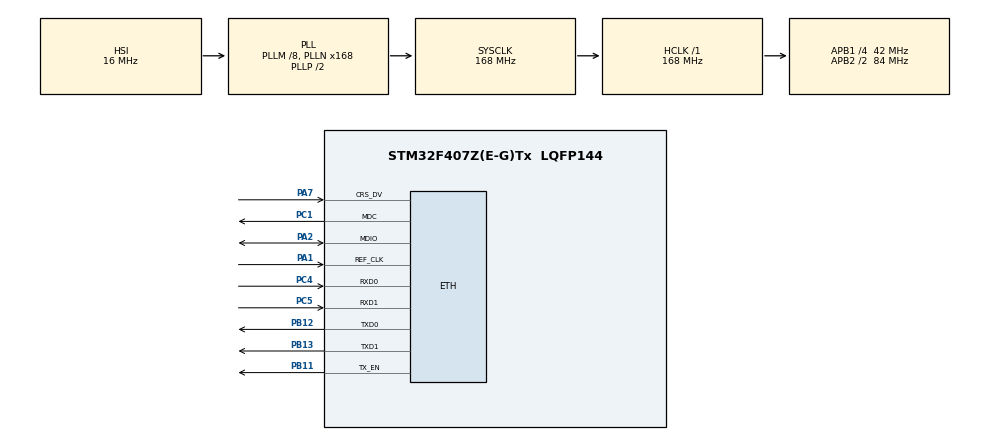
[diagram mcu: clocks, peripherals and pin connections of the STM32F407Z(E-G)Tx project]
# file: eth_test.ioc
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ETH.MediaInterface=HAL_ETH_RMII_MODE
LWIP.BSP.number=1
LWIP.MEM_SIZE=3000
LWIP.Version=v2.1.2_Cube
LWIP0.BSP.STBoard=false
LWIP0.BSP.api=BSP_COMPONENT_DRIVER
LWIP0.BSP.component=LAN8742
LWIP0.BSP.i2caddr=0
LWIP0.BSP.instance=LAN8742
LWIP0.BSP.name=Driver_PHY
LWIP0.BSP.semaphore=S_LAN8742
LWIP0.BSP.solution=LAN8742
Mcu.Family=STM32F4
Mcu.Name=STM32F407Z(E-G)Tx
Mcu.Package=LQFP144
NVIC.ETH_IRQn=true\:5\:0\:true\:false\:true\:true\:true\:true
NVIC.PriorityGroup=NVIC_PRIORITYGROUP_4
PA1.Mode=RMII
PA1.Signal=ETH_REF_CLK
PA2.Mode=RMII
PA2.Signal=ETH_MDIO
PA7.Mode=RMII
PA7.Signal=ETH_CRS_DV
PB11.Mode=RMII
PB11.Signal=ETH_TX_EN
PB12.Mode=RMII
PB12.Signal=ETH_TXD0
PB13.Mode=RMII
PB13.Signal=ETH_TXD1
PC1.Mode=RMII
PC1.Signal=ETH_MDC
PC4.Mode=RMII
PC4.Signal=ETH_RXD0
PC5.Mode=RMII
PC5.Signal=ETH_RXD1
ProjectManager.HeapSize=0x200
ProjectManager.StackSize=0x400
ProjectManager.TargetToolchain=STM32CubeIDE
RCC.48MHZClocksFreq_Value=84000000
RCC.AHBFreq_Value=168000000
RCC.APB1CLKDivider=RCC_HCLK_DIV4
RCC.APB1Freq_Value=42000000
RCC.APB1TimFreq_Value=84000000
RCC.APB2CLKDivider=RCC_HCLK_DIV2
RCC.APB2Freq_Value=84000000
RCC.APB2TimFreq_Value=168000000
RCC.CortexFreq_Value=168000000
RCC.HCLKFreq_Value=168000000
RCC.HSE_VALUE=25000000
RCC.HSI_VALUE=16000000
RCC.LSE_VALUE=32768
RCC.PLLM=8
RCC.PLLN=168
RCC.SYSCLKFreq_VALUE=168000000
RCC.SYSCLKSource=RCC_SYSCLKSOURCE_PLLCLK
RCC.VCOOutputFreq_Value=336000000
VP_LWIP_VS_Enabled.Mode=Enabled
board=custom

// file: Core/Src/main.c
/* USER CODE BEGIN Header */
/**
  ******************************************************************************
  * @file           : main.c
  * @brief          : Main program body
  ******************************************************************************
  * @attention
  *
  * Copyright (c) 2022 STMicroelectronics.
  * All rights reserved.
  *
  * This software is licensed under terms that can be found in the LICENSE file
  * in the root directory of this software component.
  * If no LICENSE file comes with this software, it is provided AS-IS.
  *
  ******************************************************************************
  */
/* USER CODE END Header */
#include "main.h"
#include "lwip.h"
#include "lwip/udp.h"
#include "lwip/ip_addr.h"

/* USER CODE BEGIN Includes */
#include <stm32f4xx_hal.h>

/* USER CODE END Includes */

void SystemClock_Config(void);
static void MX_GPIO_Init(void);

int main(void)
{

  /* MCU Configuration--------------------------------------------------------*/

  /* Reset of all peripherals, Initializes the Flash interface and the Systick. */
  HAL_Init();

  /* Configure the system clock */
  SystemClock_Config();

  /* Initialize all configured peripherals */
  MX_GPIO_Init();
  MX_LWIP_Init();

  /* Infinite loop */
  /* USER CODE BEGIN WHILE */

#define AGENT_IP "192.168.1.83"
#define AGENT_PORT 8888

	ip_addr_t pc_ipaddr;
	IP4_ADDR(&pc_ipaddr,  192, 168,   1, 83);

  struct udp_pcb * pcb = udp_new();
  udp_bind(pcb, IP_ADDR_ANY, 7000);
	udp_connect(pcb, &pc_ipaddr, AGENT_PORT);

  extern struct netif gnetif;
  pcb->netif_idx = netif_get_index(&gnetif);

  struct pbuf *p;
  p = pbuf_alloc(PBUF_TRANSPORT,100,PBUF_RAM);
//  unsigned char buffer[100] = {};
//
//  p->payload = buffer;
//  p->len = 100;
  memset(p->payload, 0xAB, 100);
  p->tot_len = 100;

  while (1)
  {
    /* USER CODE END WHILE */

	  if(gnetif.ip_addr.addr != 0) {
		 err_t err = udp_send(pcb,p);
	  }

	  MX_LWIP_Process();

  }
}

void SystemClock_Config(void)
{
  RCC_OscInitTypeDef RCC_OscInitStruct = {0};
  RCC_ClkInitTypeDef RCC_ClkInitStruct = {0};

  /** Configure the main internal regulator output voltage
  */
  __HAL_RCC_PWR_CLK_ENABLE();
  __HAL_PWR_VOLTAGESCALING_CONFIG(PWR_REGULATOR_VOLTAGE_SCALE1);

  /** Initializes the RCC Oscillators according to the specified parameters
  * in the RCC_OscInitTypeDef structure.
  */
  RCC_OscInitStruct.OscillatorType = RCC_OSCILLATORTYPE_HSI;
  RCC_OscInitStruct.HSIState = RCC_HSI_ON;
  RCC_OscInitStruct.HSICalibrationValue = RCC_HSICALIBRATION_DEFAULT;
  RCC_OscInitStruct.PLL.PLLState = RCC_PLL_ON;
  RCC_OscInitStruct.PLL.PLLSource = RCC_PLLSOURCE_HSI;
  RCC_OscInitStruct.PLL.PLLM = 8;
  RCC_OscInitStruct.PLL.PLLN = 168;
  RCC_OscInitStruct.PLL.PLLP = RCC_PLLP_DIV2;
  RCC_OscInitStruct.PLL.PLLQ = 4;
  if (HAL_RCC_OscConfig(&RCC_OscInitStruct) != HAL_OK)
  {
    Error_Handler();
  }

  /** Initializes the CPU, AHB and APB buses clocks
  */
  RCC_ClkInitStruct.ClockType = RCC_CLOCKTYPE_HCLK|RCC_CLOCKTYPE_SYSCLK
                              |RCC_CLOCKTYPE_PCLK1|RCC_CLOCKTYPE_PCLK2;
  RCC_ClkInitStruct.SYSCLKSource = RCC_SYSCLKSOURCE_PLLCLK;
  RCC_ClkInitStruct.AHBCLKDivider = RCC_SYSCLK_DIV1;
  RCC_ClkInitStruct.APB1CLKDivider = RCC_HCLK_DIV4;
  RCC_ClkInitStruct.APB2CLKDivider = RCC_HCLK_DIV2;

  if (HAL_RCC_ClockConfig(&RCC_ClkInitStruct, FLASH_LATENCY_5) != HAL_OK)
  {
    Error_Handler();
  }
}

static void MX_GPIO_Init(void)
{

  /* GPIO Ports Clock Enable */
  __HAL_RCC_GPIOC_CLK_ENABLE();
  __HAL_RCC_GPIOA_CLK_ENABLE();
  __HAL_RCC_GPIOB_CLK_ENABLE();

}

void Error_Handler(void)
{
  __disable_irq();
  while (1)
  {
  }
}
